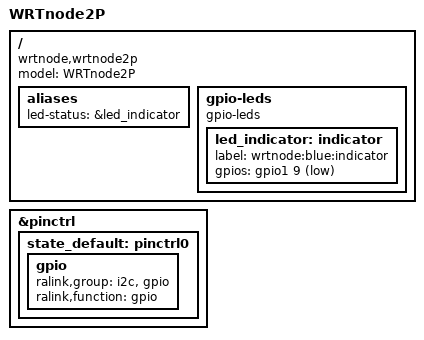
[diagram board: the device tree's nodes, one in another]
/dts-v1/;

#include "WRTNODE2.dtsi"

/ {
	compatible = "wrtnode,wrtnode2p", "wrtnode,wrtnode2", "mediatek,mt7628an-soc";
	model = "WRTnode2P";

	aliases {
		led-status = &led_indicator;
	};

	gpio-leds {
		compatible = "gpio-leds";

		led_indicator: indicator {
			label = "wrtnode:blue:indicator";
			gpios = <&gpio1 9 GPIO_ACTIVE_LOW>;
		};
	};
};

&pinctrl {
	state_default: pinctrl0 {
		gpio {
			ralink,group = "i2c", "gpio";
			ralink,function = "gpio";
		};
	};
};
